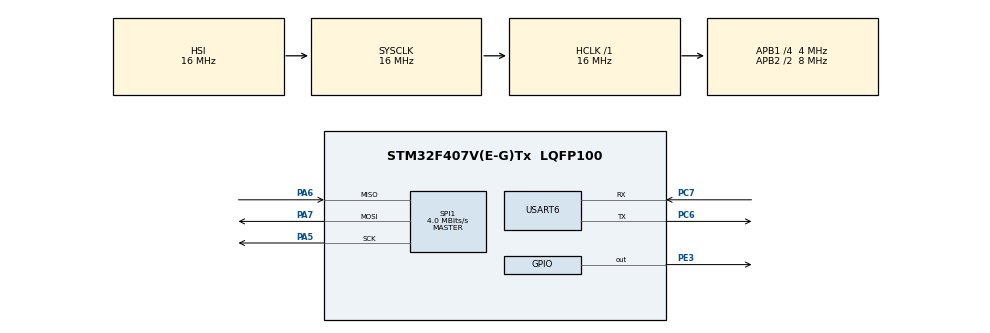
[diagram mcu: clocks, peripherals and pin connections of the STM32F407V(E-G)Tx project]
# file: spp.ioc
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Mcu.Family=STM32F4
Mcu.Name=STM32F407V(E-G)Tx
Mcu.Package=LQFP100
NVIC.PriorityGroup=NVIC_PRIORITYGROUP_0
NVIC.TIM8_TRG_COM_TIM14_IRQn=true\:0\:0\:false\:false\:true\:false\:true\:true
NVIC.TimeBase=TIM8_TRG_COM_TIM14_IRQn
NVIC.TimeBaseIP=TIM14
PA13.Mode=Serial_Wire
PA13.Signal=SYS_JTMS-SWDIO
PA14.Mode=Serial_Wire
PA14.Signal=SYS_JTCK-SWCLK
PA5.Mode=Full_Duplex_Master
PA5.Signal=SPI1_SCK
PA6.Mode=Full_Duplex_Master
PA6.Signal=SPI1_MISO
PA7.Mode=Full_Duplex_Master
PA7.Signal=SPI1_MOSI
PC6.Mode=Asynchronous
PC6.Signal=USART6_TX
PC7.Mode=Asynchronous
PC7.Signal=USART6_RX
PE3.Signal=GPIO_Output
ProjectManager.HeapSize=0x200
ProjectManager.StackSize=0x400
ProjectManager.TargetToolchain=MDK-ARM V5.32
RCC.48MHZClocksFreq_Value=14285714.285714285
RCC.AHBFreq_Value=16000000
RCC.APB1CLKDivider=RCC_HCLK_DIV4
RCC.APB1Freq_Value=4000000
RCC.APB1TimFreq_Value=8000000
RCC.APB2CLKDivider=RCC_HCLK_DIV2
RCC.APB2Freq_Value=8000000
RCC.APB2TimFreq_Value=16000000
RCC.CortexFreq_Value=16000000
RCC.HCLKFreq_Value=16000000
RCC.HSE_VALUE=8000000
RCC.HSI_VALUE=16000000
RCC.LSE_VALUE=32768
RCC.PLLM=8
RCC.PLLN=50
RCC.PLLQ=7
RCC.SYSCLKFreq_VALUE=16000000
RCC.VCOOutputFreq_Value=100000000
SPI1.BaudRatePrescaler=SPI_BAUDRATEPRESCALER_2
SPI1.CalculateBaudRate=4.0 MBits/s
SPI1.Direction=SPI_DIRECTION_2LINES
SPI1.Mode=SPI_MODE_MASTER
SPI1.VirtualType=VM_MASTER
USART6.VirtualMode=VM_ASYNC
VP_SYS_VS_tim14.Mode=TIM14
board=STM32F407G-DISC1

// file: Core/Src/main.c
/* USER CODE BEGIN Header */
/**
  ******************************************************************************
  * @file           : main.c
  * @brief          : Main program body
  ******************************************************************************
  * @attention
  *
  * Copyright (c) 2022 STMicroelectronics.
  * All rights reserved.
  *
  * This software is licensed under terms that can be found in the LICENSE file
  * in the root directory of this software component.
  * If no LICENSE file comes with this software, it is provided AS-IS.
  *
  ******************************************************************************
  */
/* USER CODE END Header */
#include "main.h"
#include<stdio.h>

/* USER CODE BEGIN PM */
uint8_t TxBuf[2],RxBuf[2];
uint8_t TxBufy[2],RxBufy[2];
uint8_t TxBufz[2],RxBufz[2];
uint8_t xaxis[2],yaxis[2],zaxis[2];
char A1[10],A2[10],A3[10];

/* USER CODE END PM */

 SPI_HandleTypeDef hspi1;

UART_HandleTypeDef huart6;

void SystemClock_Config(void);
static void MX_GPIO_Init(void);
static void MX_SPI1_Init(void);
static void MX_USART6_UART_Init(void);

int main(void)
{

  /* MCU Configuration--------------------------------------------------------*/

  /* Reset of all peripherals, Initializes the Flash interface and the Systick. */
  HAL_Init();

  /* Configure the system clock */
  SystemClock_Config();

  /* Initialize all configured peripherals */
  MX_GPIO_Init();
  MX_SPI1_Init();
  MX_USART6_UART_Init();
  /* USER CODE BEGIN 2 */
HAL_GPIO_WritePin(GPIOE,GPIO_PIN_3,GPIO_PIN_RESET);
TxBuf[0]=0x20;
TxBuf[1]=0x17;
HAL_SPI_Transmit(&hspi1,TxBuf,2,50);
HAL_GPIO_WritePin(GPIOE,GPIO_PIN_3,GPIO_PIN_SET);

  /* USER CODE END 2 */

  /* Infinite loop */
  while (1)
  {
HAL_GPIO_WritePin(GPIOE,GPIO_PIN_3,GPIO_PIN_RESET);
	TxBuf[0]=0x29|0x80;
	HAL_SPI_Transmit(&hspi1,TxBuf,1,50);
 A1[0]=HAL_SPI_Receive(&hspi1,xaxis,1,50);
				HAL_GPIO_WritePin(GPIOE,GPIO_PIN_3,GPIO_PIN_SET);
		HAL_Delay(300);

		HAL_GPIO_WritePin(GPIOE,GPIO_PIN_3,GPIO_PIN_RESET);
	TxBufy[0]=0x2B|0x80;
	HAL_SPI_Transmit(&hspi1,TxBufy,1,50);
	A2[0]=HAL_SPI_Receive(&hspi1,yaxis,1,50);
				HAL_GPIO_WritePin(GPIOE,GPIO_PIN_3,GPIO_PIN_SET);
				HAL_Delay(300);

		HAL_GPIO_WritePin(GPIOE,GPIO_PIN_3,GPIO_PIN_RESET);
	TxBufz[0]=0x2D|0x80;
	HAL_SPI_Transmit(&hspi1,TxBufz,1,50);
	A3[0]=HAL_SPI_Receive(&hspi1,zaxis,1,50);
				HAL_GPIO_WritePin(GPIOE,GPIO_PIN_3,GPIO_PIN_SET);
				HAL_Delay(300);

	HAL_UART_Transmit(&huart6,(uint8_t *)A1,sprintf(A1,"X-Axis = %d \n\r",xaxis[0]),1000);
HAL_UART_Transmit(&huart6,(uint8_t *)A2,sprintf(A2,"y-Axis = %d \n\r",yaxis[0]),1000);
HAL_UART_Transmit(&huart6,(uint8_t *)A3,sprintf(A3,"z-Axis = %d \n\r",zaxis[0]),2000);

  }
}

void SystemClock_Config(void)
{
  RCC_OscInitTypeDef RCC_OscInitStruct = {0};
  RCC_ClkInitTypeDef RCC_ClkInitStruct = {0};

  /** Configure the main internal regulator output voltage
  */
  __HAL_RCC_PWR_CLK_ENABLE();
  __HAL_PWR_VOLTAGESCALING_CONFIG(PWR_REGULATOR_VOLTAGE_SCALE1);

  /** Initializes the RCC Oscillators according to the specified parameters
  * in the RCC_OscInitTypeDef structure.
  */
  RCC_OscInitStruct.OscillatorType = RCC_OSCILLATORTYPE_HSI;
  RCC_OscInitStruct.HSIState = RCC_HSI_ON;
  RCC_OscInitStruct.HSICalibrationValue = RCC_HSICALIBRATION_DEFAULT;
  RCC_OscInitStruct.PLL.PLLState = RCC_PLL_NONE;
  if (HAL_RCC_OscConfig(&RCC_OscInitStruct) != HAL_OK)
  {
    Error_Handler();
  }

  /** Initializes the CPU, AHB and APB buses clocks
  */
  RCC_ClkInitStruct.ClockType = RCC_CLOCKTYPE_HCLK|RCC_CLOCKTYPE_SYSCLK
                              |RCC_CLOCKTYPE_PCLK1|RCC_CLOCKTYPE_PCLK2;
  RCC_ClkInitStruct.SYSCLKSource = RCC_SYSCLKSOURCE_HSI;
  RCC_ClkInitStruct.AHBCLKDivider = RCC_SYSCLK_DIV1;
  RCC_ClkInitStruct.APB1CLKDivider = RCC_HCLK_DIV4;
  RCC_ClkInitStruct.APB2CLKDivider = RCC_HCLK_DIV2;

  if (HAL_RCC_ClockConfig(&RCC_ClkInitStruct, FLASH_LATENCY_0) != HAL_OK)
  {
    Error_Handler();
  }
}

static void MX_SPI1_Init(void)
{

  /* SPI1 parameter configuration*/
  hspi1.Instance = SPI1;
  hspi1.Init.Mode = SPI_MODE_MASTER;
  hspi1.Init.Direction = SPI_DIRECTION_2LINES;
  hspi1.Init.DataSize = SPI_DATASIZE_8BIT;
  hspi1.Init.CLKPolarity = SPI_POLARITY_LOW;
  hspi1.Init.CLKPhase = SPI_PHASE_1EDGE;
  hspi1.Init.NSS = SPI_NSS_SOFT;
  hspi1.Init.BaudRatePrescaler = SPI_BAUDRATEPRESCALER_2;
  hspi1.Init.FirstBit = SPI_FIRSTBIT_MSB;
  hspi1.Init.TIMode = SPI_TIMODE_DISABLE;
  hspi1.Init.CRCCalculation = SPI_CRCCALCULATION_DISABLE;
  hspi1.Init.CRCPolynomial = 10;
  if (HAL_SPI_Init(&hspi1) != HAL_OK)
  {
    Error_Handler();
  }

}

static void MX_USART6_UART_Init(void)
{

  huart6.Instance = USART6;
  huart6.Init.BaudRate = 115200;
  huart6.Init.WordLength = UART_WORDLENGTH_8B;
  huart6.Init.StopBits = UART_STOPBITS_1;
  huart6.Init.Parity = UART_PARITY_NONE;
  huart6.Init.Mode = UART_MODE_TX_RX;
  huart6.Init.HwFlowCtl = UART_HWCONTROL_NONE;
  huart6.Init.OverSampling = UART_OVERSAMPLING_16;
  if (HAL_UART_Init(&huart6) != HAL_OK)
  {
    Error_Handler();
  }

}

static void MX_GPIO_Init(void)
{
  GPIO_InitTypeDef GPIO_InitStruct = {0};

  /* GPIO Ports Clock Enable */
  __HAL_RCC_GPIOE_CLK_ENABLE();
  __HAL_RCC_GPIOA_CLK_ENABLE();
  __HAL_RCC_GPIOC_CLK_ENABLE();

  /*Configure GPIO pin Output Level */
  HAL_GPIO_WritePin(GPIOE, GPIO_PIN_3, GPIO_PIN_RESET);

  /*Configure GPIO pin : PE3 */
  GPIO_InitStruct.Pin = GPIO_PIN_3;
  GPIO_InitStruct.Mode = GPIO_MODE_OUTPUT_PP;
  GPIO_InitStruct.Pull = GPIO_NOPULL;
  GPIO_InitStruct.Speed = GPIO_SPEED_FREQ_LOW;
  HAL_GPIO_Init(GPIOE, &GPIO_InitStruct);

}

void HAL_TIM_PeriodElapsedCallback(TIM_HandleTypeDef *htim)
{
  if (htim->Instance == TIM14) {
    HAL_IncTick();
  }
}

void Error_Handler(void)
{
  __disable_irq();
  while (1)
  {
  }
}
